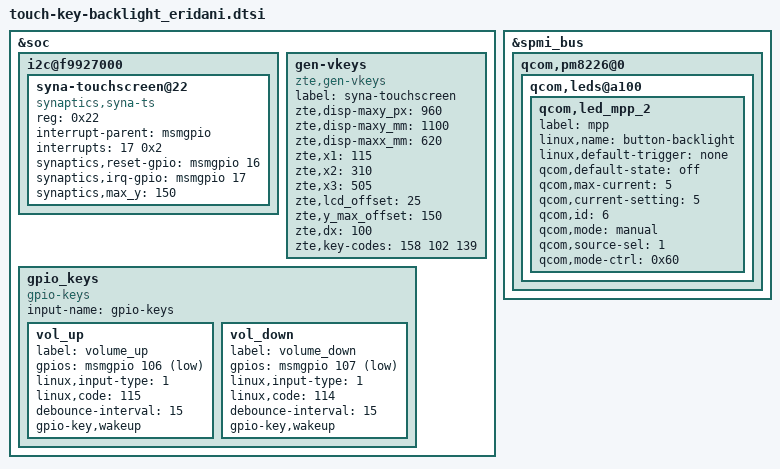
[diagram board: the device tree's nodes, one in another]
//for touchscreen and key and keypad-backlight

&soc {

i2c@f9927000 {
			syna-touchscreen@22 {
				compatible = "synaptics,syna-ts";
				reg = <0x22>;
				interrupt-parent = <&msmgpio>;
				interrupts = <17 0x2>;
				synaptics,reset-gpio = <&msmgpio 16 0x00>;
				synaptics,irq-gpio = <&msmgpio 17 0x00>;
				synaptics,max_y = <150>;
	//			vdd-supply = <&pm8226_l19>;
	//			vcc_i2c-supply = <&pm8226_lvs1>;
			};
		};
	
		gen-vkeys {
			compatible = "zte,gen-vkeys";
			label = "syna-touchscreen";
			zte,disp-maxy_px = <960>;
			zte,disp-maxy_mm = <1100>;//0.1mm
			zte,disp-maxx_mm = <620>;//0.1mm
			zte,x1=<115>;
			zte,x2=<310>;
			zte,x3=<505>;
			zte,lcd_offset=<25>;//距离LCD至少2mm 这里再放宽0.5mm
			zte,y_max_offset=<150>;//默认值LCD下边沿到按键下边沿距离估计取大值做余量
			zte,dx=<100>;//标准中X范围为5mm+-1mm取中值*2
			zte,key-codes = <158 102 139>;
		};

	
	gpio_keys {
			compatible = "gpio-keys";
			input-name = "gpio-keys";
	
			vol_up {
				label = "volume_up";
				gpios = <&msmgpio 106 0x1>;
				linux,input-type = <1>;
				linux,code = <115>;
				debounce-interval = <15>;
				gpio-key,wakeup;
			};
			/*ergate*/
			vol_down {
				label = "volume_down";
				gpios = <&msmgpio 107 0x1>;
				linux,input-type = <1>;
				linux,code = <114>;
				debounce-interval = <15>;
				gpio-key,wakeup;
			};

		};

};
&spmi_bus {
	qcom,pm8226@0 {
		qcom,leds@a100 {
			status = "okay";
			qcom,led_mpp_2 {
				label = "mpp";
				linux,name = "button-backlight";
				linux,default-trigger = "none";
				qcom,default-state = "off";
				qcom,max-current = <5>;
				qcom,current-setting = <5>;
				qcom,id = <6>;
				qcom,mode = "manual";
				qcom,source-sel = <1>;
				qcom,mode-ctrl = <0x60>;
			};
		};
	};
};
